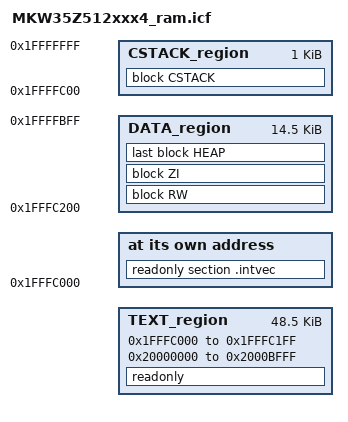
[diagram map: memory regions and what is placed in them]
/*
** ###################################################################
**     Processor:           MKW35Z512VHT4
**     Compiler:            IAR ANSI C/C++ Compiler for ARM
**     Reference manual:    MKW36A512RM Rev. 7, 07/2019
**     Version:             rev. 1.4, 2019-01-25
**     Build:               b190125
**
**     Abstract:
**         Linker file for the IAR ANSI C/C++ Compiler for ARM
**
**     Copyright 2016 Freescale Semiconductor, Inc.
**     Copyright 2016-2019 NXP
**     All rights reserved.
**
**     SPDX-License-Identifier: BSD-3-Clause
**
**     http:                 www.nxp.com
**     mail:                 support@nxp.com
**
** ###################################################################
*/

define symbol m_interrupts_start       = 0x1FFFC000;
define symbol m_interrupts_end         = 0x1FFFC1FF;

define symbol m_data_start             = 0x1FFFC200;
define symbol m_data_end               = 0x1FFFFFFF;

define symbol m_text_start             = 0x20000000;
define symbol m_text_end               = 0x2000BFFF;

/* Sizes */
if (isdefinedsymbol(__stack_size__)) {
  define symbol __size_cstack__        = __stack_size__;
} else {
  define symbol __size_cstack__        = 0x0400;
}

if (isdefinedsymbol(__heap_size__)) {
  define symbol __size_heap__          = __heap_size__;
} else {
  define symbol __size_heap__          = 0x0400;
}

define exported symbol __VECTOR_TABLE  = m_interrupts_start;
define exported symbol __VECTOR_RAM    = m_interrupts_start;
define exported symbol __RAM_VECTOR_TABLE_SIZE = 0x0;

define memory mem with size = 4G;
define region TEXT_region = mem:[from m_interrupts_start to m_interrupts_end]
                          | mem:[from m_text_start to m_text_end];
define region DATA_region = mem:[from m_data_start to m_data_end-__size_cstack__];
define region CSTACK_region = mem:[from m_data_end-__size_cstack__+1 to m_data_end];

define block CSTACK    with alignment = 8, size = __size_cstack__   { };
define block HEAP      with alignment = 8, size = __size_heap__     { };
define block RW        { readwrite };
define block ZI        { zi };

initialize by copy { readwrite, section .textrw };
do not initialize  { section .noinit };

place at address mem: m_interrupts_start    { readonly section .intvec };
place in TEXT_region                        { readonly };
place in DATA_region                        { block RW };
place in DATA_region                        { block ZI };
place in DATA_region                        { last block HEAP };
place in CSTACK_region                      { block CSTACK };

